# ATSAMA5D27WLSOM1 device description
Architecture: CORTEX-A5; Family: SAMA5; Series: SAMA5D2
Registers are 32-bit, read-write, no defined reset value unless marked. A register's access mark holds for its fields unless they carry their own. Offsets are from the block's base; [hi:lo] are bit positions; {n}, {i} and the like mark numbered series.

## UHPHS — USB Host High Speed Port
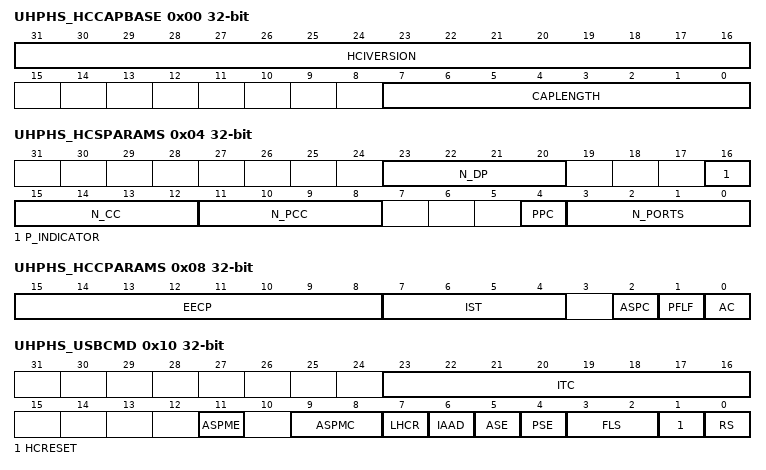
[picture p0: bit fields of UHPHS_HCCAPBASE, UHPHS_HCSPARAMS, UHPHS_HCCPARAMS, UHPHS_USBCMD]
0x00 UHPHS_HCCAPBASE ro — UHPHS Host Controller Capability Register
  [31:16] HCIVERSION — Host Controller Interface Version Number
  [7:0] CAPLENGTH — Capability Registers Length
0x04 UHPHS_HCSPARAMS ro — UHPHS Host Controller Structural Parameters Register
  [23:20] N_DP — Debug Port Number
  [16] P_INDICATOR — Port Indicators
  [15:12] N_CC — Number of Companion Controllers
  [11:8] N_PCC — Number of Ports per Companion Controller
  [4] PPC — Port Power Control
  [3:0] N_PORTS — Number of Ports
0x08 UHPHS_HCCPARAMS ro — UHPHS Host Controller Capability Parameters Register
  [15:8] EECP — EHCI Extended Capabilities Pointer
  [7:4] IST — Isochronous Scheduling Threshold
  [2] ASPC — Asynchronous Schedule Park Capability
  [1] PFLF — Programmable Frame List Flag
  [0] AC — 64-bit Addressing Capability
0x10 UHPHS_USBCMD — UHPHS USB Command Register
  [23:16] ITC — Interrupt Threshold Control (read/write)
  [11] ASPME — Asynchronous Schedule Park Mode Enable (optional) (read/write or read-only)
  [9:8] ASPMC — Asynchronous Schedule Park Mode Count (optional) (read/write or read-only)
  [7] LHCR — Light Host Controller Reset (optional) (read/write)
  [6] IAAD — Interrupt on Async Advance Doorbell (read/write)
  [5] ASE — Asynchronous Schedule Enable (read/write)
  [4] PSE — Periodic Schedule Enable (read/write)
  [3:2] FLS — Frame List Size (read/write or read-only)
  [1] HCRESET — Host Controller Reset (read/write)
  [0] RS — Run/Stop (read/write)
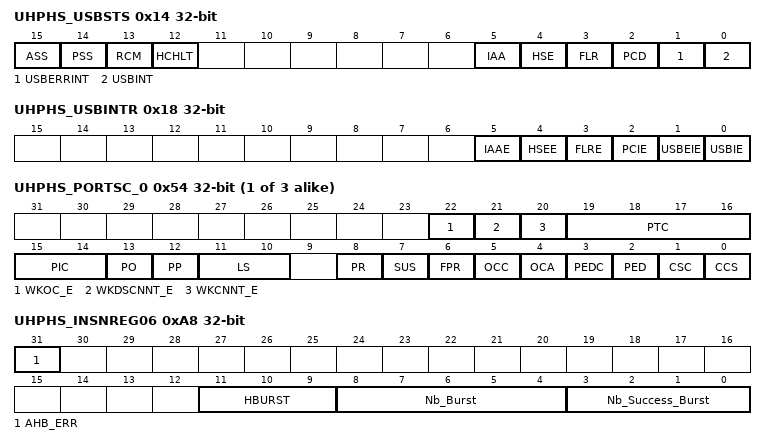
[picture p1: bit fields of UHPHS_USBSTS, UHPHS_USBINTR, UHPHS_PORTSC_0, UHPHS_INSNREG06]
0x14 UHPHS_USBSTS — UHPHS USB Status Register
  [15] ASS — Asynchronous Schedule Status (read-only)
  [14] PSS — Periodic Schedule Status (read-only)
  [13] RCM — Reclamation (read-only)
  [12] HCHLT — HCHalted (read-only)
  [5] IAA — Interrupt on Async Advance (read/write clear)
  [4] HSE — Host System Error (read/write clear)
  [3] FLR — Frame List Rollover (read/write clear)
  [2] PCD — Port Change Detect (read/write clear)
  [1] USBERRINT — USB Error Interrupt (read/write clear)
  [0] USBINT — USB Interrupt (read/write clear)
0x18 UHPHS_USBINTR — UHPHS USB Interrupt Enable Register
  [5] IAAE — Interrupt on Async Advance Enable
  [4] HSEE — Host System Error Enable
  [3] FLRE — Frame List Rollover Enable
  [2] PCIE — Port Change Interrupt Enable
  [1] USBEIE — USB Error Interrupt Enable
  [0] USBIE — USB Interrupt Enable
0x1C UHPHS_FRINDEX — UHPHS USB Frame Index Register
  [13:0] FI — Frame Index
0x24 UHPHS_PERIODICLISTBASE — UHPHS Periodic Frame List Base Address Register
  [31:12] BA — Base Address (Low)
0x28 UHPHS_ASYNCLISTADDR — UHPHS Asynchronous List Address Register
  [31:5] LPL — Link Pointer Low
0x50 UHPHS_CONFIGFLAG — UHPHS Configured Flag Register
  [0] CF — Configure Flag (read/write)
{0x54+4i} UHPHS_PORTSC_{i} (i=0..2) — UHPHS Port Status and Control Register {i}
  [22] WKOC_E — Wake on Over-current Enable (read/write)
  [21] WKDSCNNT_E — Wake on Disconnect Enable (read/write)
  [20] WKCNNT_E — Wake on Connect Enable (read/write)
  [19:16] PTC — Port Test Control (read/write)
  [15:14] PIC — Port Indicator Control (read/write)
  [13] PO — Port Owner (read/write)
  [12] PP — Port Power (read/write or read-only)
  [11:10] LS — Line Status (read-only)
  [8] PR — Port Reset (read/write)
  [7] SUS — Suspend (read/write)
  [6] FPR — Force Port Resume (read/write)
  [5] OCC — Over-current Change (read/write clear)
  [4] OCA — Over-current Active (read-only)
  [3] PEDC — Port Enable/Disable Change (read/write clear)
  [2] PED — Port Enabled/Disabled (read/write)
  [1] CSC — Connect Status Change (read/write clear)
  [0] CCS — Current Connect Status (read-only)
0xA8 UHPHS_INSNREG06 — EHCI Synopsys-Specific Registers 06
  [31] AHB_ERR — AHB Error
  [11:9] HBURST — Burst Value (read-only)(1)
  [8:4] Nb_Burst — Number of Bursts (read-only)(1)
  [3:0] Nb_Success_Burst — Number of Successful Bursts (read-only)(1)
0xAC UHPHS_INSNREG07 — EHCI Synopsys-Specific Registers 07
  [31:0] AHB_ADDR — AHB Address (read only)
0xB0 UHPHS_INSNREG08 — EHCI Synopsys-Specific Registers 08
  [2] HSIC_EN — HSIC Enable/Disable
